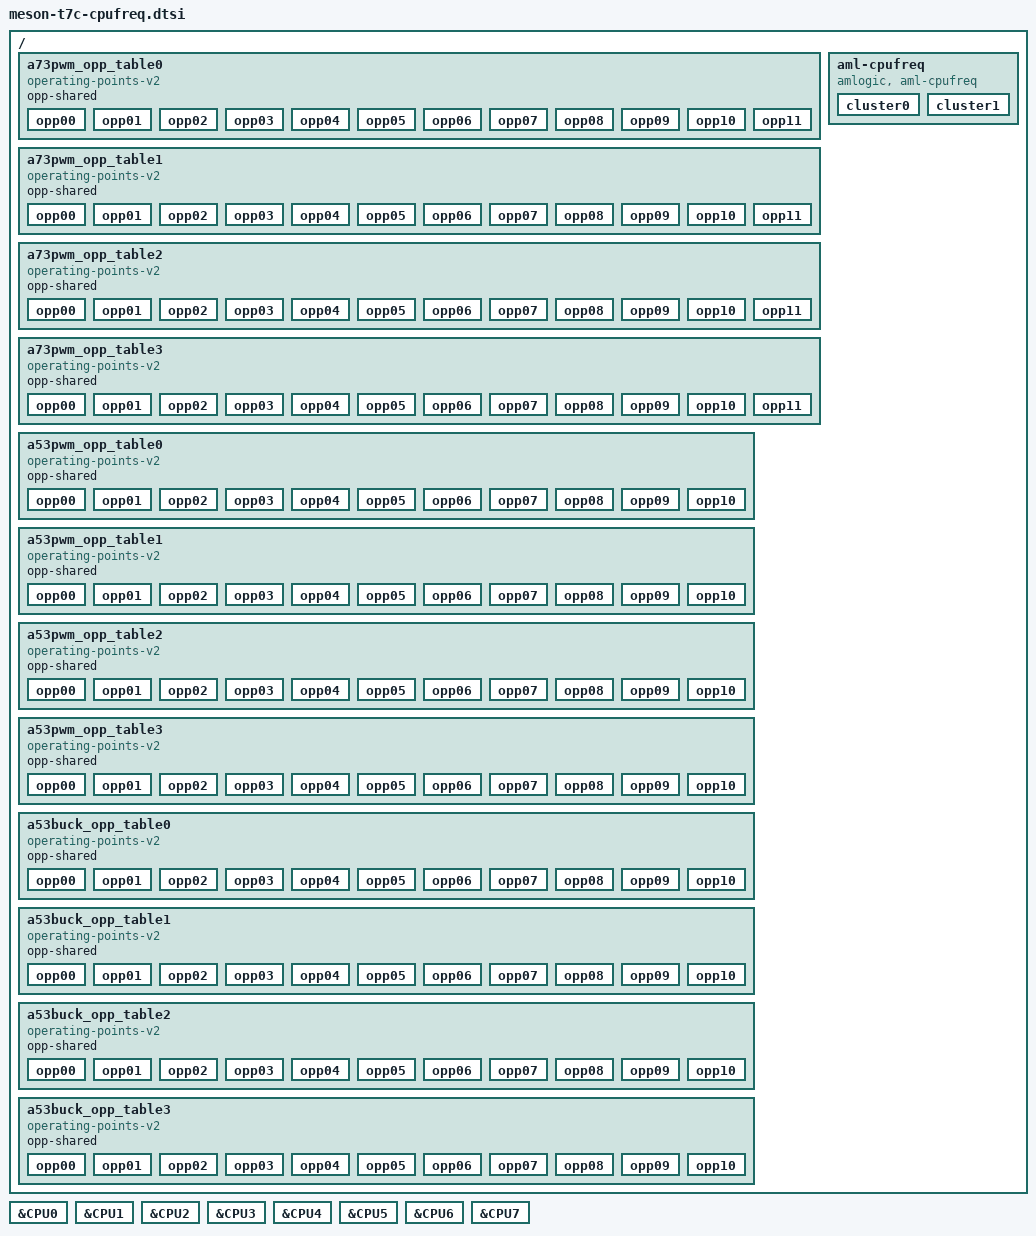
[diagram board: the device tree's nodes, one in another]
// SPDX-License-Identifier: (GPL-2.0+ OR MIT)
/*
 * Copyright (c) 2019 Amlogic, Inc. All rights reserved.
 */
/ {
	a73pwm_opp_table0: a73pwm_opp_table0 {
		compatible = "operating-points-v2";
		opp-shared;

		opp00 {
			opp-hz = /bits/ 64 <500000000>;
			opp-microvolt = <819000>;
		};
		opp01 {
			opp-hz = /bits/ 64 <666666666>;
			opp-microvolt = <819000>;
		};
		opp02 {
			opp-hz = /bits/ 64 <1000000000>;
			opp-microvolt = <819000>;
		};
		opp03 {
			opp-hz = /bits/ 64 <1200000000>;
			opp-microvolt = <819000>;
		};
		opp04 {
			opp-hz = /bits/ 64 <1392000000>;
			opp-microvolt = <819000>;
		};
		opp05 {
			opp-hz = /bits/ 64 <1512000000>;
			opp-microvolt = <829000>;
		};
		opp06 {
			opp-hz = /bits/ 64 <1608000000>;
			opp-microvolt = <849000>;
		};
		opp07 {
			opp-hz = /bits/ 64 <1704000000>;
			opp-microvolt = <869000>;
		};
		opp08 {
			opp-hz = /bits/ 64 <1800000000>;
			opp-microvolt = <909000>;
		};
		opp09 {
			opp-hz = /bits/ 64 <1896000000>;
			opp-microvolt = <939000>;
		};
		opp10 {
			opp-hz = /bits/ 64 <2016000000>;
			opp-microvolt = <959000>;
		};
		opp11 {
			opp-hz = /bits/ 64 <2208000000>;
			opp-microvolt = <1009000>;
		};
	};

	a73pwm_opp_table1: a73pwm_opp_table1 {
		compatible = "operating-points-v2";
		opp-shared;

		opp00 {
			opp-hz = /bits/ 64 <500000000>;
			opp-microvolt = <819000>;
		};
		opp01 {
			opp-hz = /bits/ 64 <666666666>;
			opp-microvolt = <819000>;
		};
		opp02 {
			opp-hz = /bits/ 64 <1000000000>;
			opp-microvolt = <819000>;
		};
		opp03 {
			opp-hz = /bits/ 64 <1200000000>;
			opp-microvolt = <819000>;
		};
		opp04 {
			opp-hz = /bits/ 64 <1392000000>;
			opp-microvolt = <819000>;
		};
		opp05 {
			opp-hz = /bits/ 64 <1512000000>;
			opp-microvolt = <829000>;
		};
		opp06 {
			opp-hz = /bits/ 64 <1608000000>;
			opp-microvolt = <849000>;
		};
		opp07 {
			opp-hz = /bits/ 64 <1704000000>;
			opp-microvolt = <869000>;
		};
		opp08 {
			opp-hz = /bits/ 64 <1800000000>;
			opp-microvolt = <909000>;
		};
		opp09 {
			opp-hz = /bits/ 64 <1896000000>;
			opp-microvolt = <939000>;
		};
		opp10 {
			opp-hz = /bits/ 64 <2016000000>;
			opp-microvolt = <959000>;
		};
		opp11 {
			opp-hz = /bits/ 64 <2208000000>;
			opp-microvolt = <1009000>;
		};
	};

	a73pwm_opp_table2: a73pwm_opp_table2 {
		compatible = "operating-points-v2";
		opp-shared;

		opp00 {
			opp-hz = /bits/ 64 <500000000>;
			opp-microvolt = <799000>;
		};
		opp01 {
			opp-hz = /bits/ 64 <666666666>;
			opp-microvolt = <799000>;
		};
		opp02 {
			opp-hz = /bits/ 64 <1000000000>;
			opp-microvolt = <799000>;
		};
		opp03 {
			opp-hz = /bits/ 64 <1200000000>;
			opp-microvolt = <799000>;
		};
		opp04 {
			opp-hz = /bits/ 64 <1392000000>;
			opp-microvolt = <809000>;
		};
		opp05 {
			opp-hz = /bits/ 64 <1512000000>;
			opp-microvolt = <809000>;
		};
		opp06 {
			opp-hz = /bits/ 64 <1608000000>;
			opp-microvolt = <829000>;
		};
		opp07 {
			opp-hz = /bits/ 64 <1704000000>;
			opp-microvolt = <849000>;
		};
		opp08 {
			opp-hz = /bits/ 64 <1800000000>;
			opp-microvolt = <859000>;
		};
		opp09 {
			opp-hz = /bits/ 64 <1896000000>;
			opp-microvolt = <889000>;
		};
		opp10 {
			opp-hz = /bits/ 64 <2016000000>;
			opp-microvolt = <919000>;
		};
		opp11 {
			opp-hz = /bits/ 64 <2208000000>;
			opp-microvolt = <969000>;
		};
	};

	a73pwm_opp_table3: a73pwm_opp_table3 {
		compatible = "operating-points-v2";
		opp-shared;

		opp00 {
			opp-hz = /bits/ 64 <500000000>;
			opp-microvolt = <789000>;
		};
		opp01 {
			opp-hz = /bits/ 64 <666666666>;
			opp-microvolt = <789000>;
		};
		opp02 {
			opp-hz = /bits/ 64 <1000000000>;
			opp-microvolt = <789000>;
		};
		opp03 {
			opp-hz = /bits/ 64 <1200000000>;
			opp-microvolt = <789000>;
		};
		opp04 {
			opp-hz = /bits/ 64 <1392000000>;
			opp-microvolt = <809000>;
		};
		opp05 {
			opp-hz = /bits/ 64 <1512000000>;
			opp-microvolt = <809000>;
		};
		opp06 {
			opp-hz = /bits/ 64 <1608000000>;
			opp-microvolt = <819000>;
		};
		opp07 {
			opp-hz = /bits/ 64 <1704000000>;
			opp-microvolt = <829000>;
		};
		opp08 {
			opp-hz = /bits/ 64 <1800000000>;
			opp-microvolt = <849000>;
		};
		opp09 {
			opp-hz = /bits/ 64 <1896000000>;
			opp-microvolt = <859000>;
		};
		opp10 {
			opp-hz = /bits/ 64 <2016000000>;
			opp-microvolt = <879000>;
		};
		opp11 {
			opp-hz = /bits/ 64 <2208000000>;
			opp-microvolt = <919000>;
		};
	};

	a53pwm_opp_table0: a53pwm_opp_table0 {
		compatible = "operating-points-v2";
		opp-shared;

		opp00 {
			opp-hz = /bits/ 64 <500000000>;
			opp-microvolt = <769000>;
		};
		opp01 {
			opp-hz = /bits/ 64 <666666666>;
			opp-microvolt = <769000>;
		};
		opp02 {
			opp-hz = /bits/ 64 <1000000000>;
			opp-microvolt = <769000>;
		};
		opp03 {
			opp-hz = /bits/ 64 <1200000000>;
			opp-microvolt = <769000>;
		};
		opp04 {
			opp-hz = /bits/ 64 <1392000000>;
			opp-microvolt = <769000>;
		};
		opp05 {
			opp-hz = /bits/ 64 <1512000000>;
			opp-microvolt = <809000>;
		};
		opp06 {
			opp-hz = /bits/ 64 <1608000000>;
			opp-microvolt = <839000>;
		};
		opp07 {
			opp-hz = /bits/ 64 <1704000000>;
			opp-microvolt = <869000>;
		};
		opp08 {
			opp-hz = /bits/ 64 <1800000000>;
			opp-microvolt = <909000>;
		};
		opp09 {
			opp-hz = /bits/ 64 <1896000000>;
			opp-microvolt = <949000>;
		};
		opp10 {
			opp-hz = /bits/ 64 <2016000000>;
			opp-microvolt = <1009000>;
		};
	};

	a53pwm_opp_table1: a53pwm_opp_table1 {
		compatible = "operating-points-v2";
		opp-shared;

		opp00 {
			opp-hz = /bits/ 64 <500000000>;
			opp-microvolt = <769000>;
		};
		opp01 {
			opp-hz = /bits/ 64 <666666666>;
			opp-microvolt = <769000>;
		};
		opp02 {
			opp-hz = /bits/ 64 <1000000000>;
			opp-microvolt = <769000>;
		};
		opp03 {
			opp-hz = /bits/ 64 <1200000000>;
			opp-microvolt = <769000>;
		};
		opp04 {
			opp-hz = /bits/ 64 <1392000000>;
			opp-microvolt = <769000>;
		};
		opp05 {
			opp-hz = /bits/ 64 <1512000000>;
			opp-microvolt = <809000>;
		};
		opp06 {
			opp-hz = /bits/ 64 <1608000000>;
			opp-microvolt = <839000>;
		};
		opp07 {
			opp-hz = /bits/ 64 <1704000000>;
			opp-microvolt = <869000>;
		};
		opp08 {
			opp-hz = /bits/ 64 <1800000000>;
			opp-microvolt = <909000>;
		};
		opp09 {
			opp-hz = /bits/ 64 <1896000000>;
			opp-microvolt = <949000>;
		};
		opp10 {
			opp-hz = /bits/ 64 <2016000000>;
			opp-microvolt = <1009000>;
		};
	};

	a53pwm_opp_table2: a53pwm_opp_table2 {
		compatible = "operating-points-v2";
		opp-shared;

		opp00 {
			opp-hz = /bits/ 64 <500000000>;
			opp-microvolt = <759000>;
		};
		opp01 {
			opp-hz = /bits/ 64 <666666666>;
			opp-microvolt = <759000>;
		};
		opp02 {
			opp-hz = /bits/ 64 <1000000000>;
			opp-microvolt = <759000>;
		};
		opp03 {
			opp-hz = /bits/ 64 <1200000000>;
			opp-microvolt = <759000>;
		};
		opp04 {
			opp-hz = /bits/ 64 <1392000000>;
			opp-microvolt = <769000>;
		};
		opp05 {
			opp-hz = /bits/ 64 <1512000000>;
			opp-microvolt = <789000>;
		};
		opp06 {
			opp-hz = /bits/ 64 <1608000000>;
			opp-microvolt = <799000>;
		};
		opp07 {
			opp-hz = /bits/ 64 <1704000000>;
			opp-microvolt = <829000>;
		};
		opp08 {
			opp-hz = /bits/ 64 <1800000000>;
			opp-microvolt = <859000>;
		};
		opp09 {
			opp-hz = /bits/ 64 <1896000000>;
			opp-microvolt = <899000>;
		};
		opp10 {
			opp-hz = /bits/ 64 <2016000000>;
			opp-microvolt = <949000>;
		};
	};

	a53pwm_opp_table3: a53pwm_opp_table3 {
		compatible = "operating-points-v2";
		opp-shared;

		opp00 {
			opp-hz = /bits/ 64 <500000000>;
			opp-microvolt = <749000>;
		};
		opp01 {
			opp-hz = /bits/ 64 <666666666>;
			opp-microvolt = <749000>;
		};
		opp02 {
			opp-hz = /bits/ 64 <1000000000>;
			opp-microvolt = <749000>;
		};
		opp03 {
			opp-hz = /bits/ 64 <1200000000>;
			opp-microvolt = <749000>;
		};
		opp04 {
			opp-hz = /bits/ 64 <1392000000>;
			opp-microvolt = <769000>;
		};
		opp05 {
			opp-hz = /bits/ 64 <1512000000>;
			opp-microvolt = <779000>;
		};
		opp06 {
			opp-hz = /bits/ 64 <1608000000>;
			opp-microvolt = <789000>;
		};
		opp07 {
			opp-hz = /bits/ 64 <1704000000>;
			opp-microvolt = <809000>;
		};
		opp08 {
			opp-hz = /bits/ 64 <1800000000>;
			opp-microvolt = <829000>;
		};
		opp09 {
			opp-hz = /bits/ 64 <1896000000>;
			opp-microvolt = <859000>;
		};
		opp10 {
			opp-hz = /bits/ 64 <2016000000>;
			opp-microvolt = <919000>;
		};
	};

	a53buck_opp_table0: a53buck_opp_table0 {
		compatible = "operating-points-v2";
		opp-shared;

		opp00 {
			opp-hz = /bits/ 64 <500000000>;
			opp-microvolt = <770000>;
		};
		opp01 {
			opp-hz = /bits/ 64 <666666666>;
			opp-microvolt = <770000>;
		};
		opp02 {
			opp-hz = /bits/ 64 <1000000000>;
			opp-microvolt = <770000>;
		};
		opp03 {
			opp-hz = /bits/ 64 <1200000000>;
			opp-microvolt = <770000>;
		};
		opp04 {
			opp-hz = /bits/ 64 <1392000000>;
			opp-microvolt = <770000>;
		};
		opp05 {
			opp-hz = /bits/ 64 <1512000000>;
			opp-microvolt = <810000>;
		};
		opp06 {
			opp-hz = /bits/ 64 <1608000000>;
			opp-microvolt = <840000>;
		};
		opp07 {
			opp-hz = /bits/ 64 <1704000000>;
			opp-microvolt = <870000>;
		};
		opp08 {
			opp-hz = /bits/ 64 <1800000000>;
			opp-microvolt = <910000>;
		};
		opp09 {
			opp-hz = /bits/ 64 <1896000000>;
			opp-microvolt = <950000>;
		};
		opp10 {
			opp-hz = /bits/ 64 <2016000000>;
			opp-microvolt = <1010000>;
		};
	};

	a53buck_opp_table1: a53buck_opp_table1 {
		compatible = "operating-points-v2";
		opp-shared;

		opp00 {
			opp-hz = /bits/ 64 <500000000>;
			opp-microvolt = <770000>;
		};
		opp01 {
			opp-hz = /bits/ 64 <666666666>;
			opp-microvolt = <770000>;
		};
		opp02 {
			opp-hz = /bits/ 64 <1000000000>;
			opp-microvolt = <770000>;
		};
		opp03 {
			opp-hz = /bits/ 64 <1200000000>;
			opp-microvolt = <770000>;
		};
		opp04 {
			opp-hz = /bits/ 64 <1392000000>;
			opp-microvolt = <770000>;
		};
		opp05 {
			opp-hz = /bits/ 64 <1512000000>;
			opp-microvolt = <810000>;
		};
		opp06 {
			opp-hz = /bits/ 64 <1608000000>;
			opp-microvolt = <840000>;
		};
		opp07 {
			opp-hz = /bits/ 64 <1704000000>;
			opp-microvolt = <870000>;
		};
		opp08 {
			opp-hz = /bits/ 64 <1800000000>;
			opp-microvolt = <910000>;
		};
		opp09 {
			opp-hz = /bits/ 64 <1896000000>;
			opp-microvolt = <950000>;
		};
		opp10 {
			opp-hz = /bits/ 64 <2016000000>;
			opp-microvolt = <1010000>;
		};
	};

	a53buck_opp_table2: a53buck_opp_table2 {
		compatible = "operating-points-v2";
		opp-shared;

		opp00 {
			opp-hz = /bits/ 64 <500000000>;
			opp-microvolt = <760000>;
		};
		opp01 {
			opp-hz = /bits/ 64 <666666666>;
			opp-microvolt = <760000>;
		};
		opp02 {
			opp-hz = /bits/ 64 <1000000000>;
			opp-microvolt = <760000>;
		};
		opp03 {
			opp-hz = /bits/ 64 <1200000000>;
			opp-microvolt = <760000>;
		};
		opp04 {
			opp-hz = /bits/ 64 <1392000000>;
			opp-microvolt = <770000>;
		};
		opp05 {
			opp-hz = /bits/ 64 <1512000000>;
			opp-microvolt = <790000>;
		};
		opp06 {
			opp-hz = /bits/ 64 <1608000000>;
			opp-microvolt = <800000>;
		};
		opp07 {
			opp-hz = /bits/ 64 <1704000000>;
			opp-microvolt = <830000>;
		};
		opp08 {
			opp-hz = /bits/ 64 <1800000000>;
			opp-microvolt = <860000>;
		};
		opp09 {
			opp-hz = /bits/ 64 <1896000000>;
			opp-microvolt = <900000>;
		};
		opp10 {
			opp-hz = /bits/ 64 <2016000000>;
			opp-microvolt = <950000>;
		};
	};

	a53buck_opp_table3: a53buck_opp_table3 {
		compatible = "operating-points-v2";
		opp-shared;

		opp00 {
			opp-hz = /bits/ 64 <500000000>;
			opp-microvolt = <750000>;
		};
		opp01 {
			opp-hz = /bits/ 64 <666666666>;
			opp-microvolt = <750000>;
		};
		opp02 {
			opp-hz = /bits/ 64 <1000000000>;
			opp-microvolt = <750000>;
		};
		opp03 {
			opp-hz = /bits/ 64 <1200000000>;
			opp-microvolt = <750000>;
		};
		opp04 {
			opp-hz = /bits/ 64 <1392000000>;
			opp-microvolt = <770000>;
		};
		opp05 {
			opp-hz = /bits/ 64 <1512000000>;
			opp-microvolt = <780000>;
		};
		opp06 {
			opp-hz = /bits/ 64 <1608000000>;
			opp-microvolt = <790000>;
		};
		opp07 {
			opp-hz = /bits/ 64 <1704000000>;
			opp-microvolt = <810000>;
		};
		opp08 {
			opp-hz = /bits/ 64 <1800000000>;
			opp-microvolt = <830000>;
		};
		opp09 {
			opp-hz = /bits/ 64 <1896000000>;
			opp-microvolt = <860000>;
		};
		opp10 {
			opp-hz = /bits/ 64 <2016000000>;
			opp-microvolt = <920000>;
		};
	};

	aml-cpufreq {
		compatible = "amlogic, aml-cpufreq";
		status = "okay";

		cluster0-cpu-supply = <&vddcpua>;
		cluster1-cpu-supply = <&vddcpub>;

		cluster0 {
			clocks = <&scmi_clk CLKID_A73_CLK>;
			clock-names = "cpuclk";
			voltage-tolerance = <0>;
			transition_delay_us = <10000>;
			//skip_volt_scaling;
			cluster_cores = <0 1 2 3>;
			pdvfs_enabled;
		};

		cluster1 {
			clocks = <&scmi_clk CLKID_CPU_CLK>;
			clock-names = "cpuclk";
			voltage-tolerance = <0>;
			transition_delay_us = <10000>;
			//skip_volt_scaling;
			cluster_cores = <4 5 6 7>;
			pdvfs_enabled;
		};
	};
};/* end of / */

&CPU0 {
	operating-points-v2 = <&a73pwm_opp_table0>,
		<&a73pwm_opp_table1>,
		<&a73pwm_opp_table2>,
		<&a73pwm_opp_table3>;
};

&CPU1 {
	operating-points-v2 = <&a73pwm_opp_table0>,
		<&a73pwm_opp_table1>,
		<&a73pwm_opp_table2>,
		<&a73pwm_opp_table3>;
};

&CPU2 {
	operating-points-v2 = <&a73pwm_opp_table0>,
		<&a73pwm_opp_table1>,
		<&a73pwm_opp_table2>,
		<&a73pwm_opp_table3>;
};

&CPU3 {
	operating-points-v2 = <&a73pwm_opp_table0>,
		<&a73pwm_opp_table1>,
		<&a73pwm_opp_table2>,
		<&a73pwm_opp_table3>;
};

&CPU4 {
	operating-points-v2 = <&a53pwm_opp_table0>,
		<&a53pwm_opp_table1>,
		<&a53pwm_opp_table2>,
		<&a53pwm_opp_table3>;
};

&CPU5 {
	operating-points-v2 = <&a53pwm_opp_table0>,
		<&a53pwm_opp_table1>,
		<&a53pwm_opp_table2>,
		<&a53pwm_opp_table3>;
};

&CPU6 {
	operating-points-v2 = <&a53pwm_opp_table0>,
		<&a53pwm_opp_table1>,
		<&a53pwm_opp_table2>,
		<&a53pwm_opp_table3>;
};

&CPU7 {
	operating-points-v2 = <&a53pwm_opp_table0>,
		<&a53pwm_opp_table1>,
		<&a53pwm_opp_table2>,
		<&a53pwm_opp_table3>;
};
